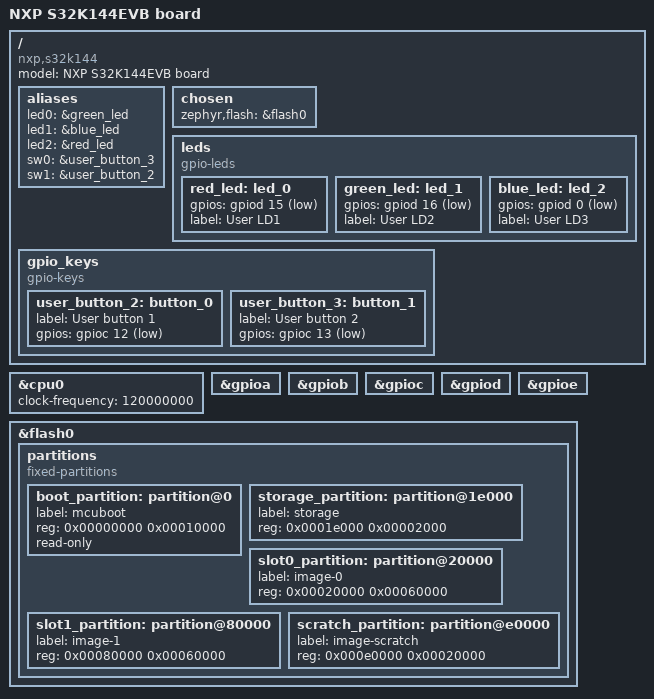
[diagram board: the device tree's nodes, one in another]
/* SPDX-License-Identifier: Apache-2.0 */

/dts-v1/;

#include <nxp/nxp_s32k144.dtsi>

/ {
	model = "NXP S32K144EVB board";
	compatible = "nxp,s32k144";

	aliases {
		led0 = &green_led;
		led1 = &blue_led;
		led2 = &red_led;
		sw0 = &user_button_3;
		sw1 = &user_button_2;
	};

	chosen {
		zephyr,flash = &flash0;
	};

	leds {
		compatible = "gpio-leds";
		red_led: led_0 {
			gpios = <&gpiod 15 GPIO_ACTIVE_LOW>;
			label = "User LD1";
		};
		green_led: led_1 {
			gpios = <&gpiod 16 GPIO_ACTIVE_LOW>;
			label = "User LD2";
		};
		blue_led: led_2 {
			gpios = <&gpiod 0 GPIO_ACTIVE_LOW>;
			label = "User LD3";
		};
	};

	gpio_keys {
		compatible = "gpio-keys";

		user_button_2: button_0 {
			label = "User button 1";
			gpios = <&gpioc 12 GPIO_ACTIVE_LOW>;
		};
		user_button_3: button_1 {
			label = "User button 2";
			gpios = <&gpioc 13 GPIO_ACTIVE_LOW>;
		};
	};	
};

&cpu0 {
	clock-frequency = <120000000>;
};

// &uart0 {
// 	status = "okay";
// 	current-speed = <115200>;
// 	pinctrl-0 = <&UART0_RX_PTB16 &UART0_TX_PTB17>;
// };

// &uart2 {
// 	pinctrl-0 = <&UART2_RTS_b_PTD0 &UART2_CTS_b_PTD1 &UART2_RX_PTD2 &UART2_TX_PTD3>;
// };

// &flash0 {

// 	partitions {
// 		compatible = "fixed-partitions";
// 		#address-cells = <1>;
// 		#size-cells = <1>;

// 		boot_partition: partition@0 {
// 			label = "mcuboot";
// 			reg = <0x00000000 0x00010000>;
// 			read-only;
// 		};

// 		/*
// 		 * The flash starting at 0x00010000 and ending at
// 		 * 0x0001ffff (sectors 16-31) is reserved for use
// 		 * by the application.
// 		 */
// 		storage_partition: partition@1e000 {
// 			label = "storage";
// 			reg = <0x0001e000 0x00002000>;
// 		};

// 		slot0_partition: partition@20000 {
// 			label = "image-0";
// 			reg = <0x00020000 0x00060000>;
// 		};
// 		slot1_partition: partition@80000 {
// 			label = "image-1";
// 			reg = <0x00080000 0x00060000>;
// 		};
// 		scratch_partition: partition@e0000 {
// 			label = "image-scratch";
// 			reg = <0x000e0000 0x00020000>;
// 		};
// 	};
// };

&gpioa {
	status = "okay";
};

&gpiob {
	status = "okay";
};

&gpioc {
	status = "okay";
};

&gpiod {
	status = "okay";
};

&gpioe {
	status = "okay";
};

// &flexcan0 {
// 	status = "okay";
// 	pinctrl-0 = <&CAN0_TX_PTB18 &CAN0_RX_PTB19>;
// 	bus-speed = <125000>;
// };

&flash0 {

	partitions {
		compatible = "fixed-partitions";
		#address-cells = <1>;
		#size-cells = <1>;

		boot_partition: partition@0 {
			label = "mcuboot";
			reg = <0x00000000 0x00010000>;
			read-only;
		};

		/*
		 * The flash starting at 0x00010000 and ending at
		 * 0x0001ffff (sectors 16-31) is reserved for use
		 * by the application.
		 */
		storage_partition: partition@1e000 {
			label = "storage";
			reg = <0x0001e000 0x00002000>;
		};

		slot0_partition: partition@20000 {
			label = "image-0";
			reg = <0x00020000 0x00060000>;
		};
		slot1_partition: partition@80000 {
			label = "image-1";
			reg = <0x00080000 0x00060000>;
		};
		scratch_partition: partition@e0000 {
			label = "image-scratch";
			reg = <0x000e0000 0x00020000>;
		};
	};
};
